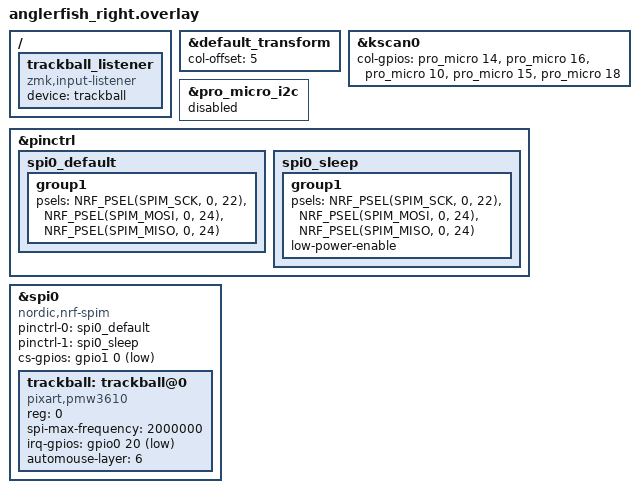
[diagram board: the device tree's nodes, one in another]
#include "anglerfish.dtsi"

&default_transform {
  col-offset = <5>;
};

&kscan0 {
  col-gpios = <&pro_micro 14 GPIO_ACTIVE_HIGH>,
              <&pro_micro 16 GPIO_ACTIVE_HIGH>,
              <&pro_micro 10 GPIO_ACTIVE_HIGH>,
              <&pro_micro 15 GPIO_ACTIVE_HIGH>,
              <&pro_micro 18 GPIO_ACTIVE_HIGH>;
};

&pro_micro_i2c {
    status = "disabled";
};

&pinctrl {
    spi0_default: spi0_default {
        group1 {
            psels = <NRF_PSEL(SPIM_SCK, 0, 22)>,
                <NRF_PSEL(SPIM_MOSI, 0, 24)>,
                <NRF_PSEL(SPIM_MISO, 0, 24)>;
        };
    };

    spi0_sleep: spi0_sleep {
        group1 {
            psels = <NRF_PSEL(SPIM_SCK, 0, 22)>,
                <NRF_PSEL(SPIM_MOSI, 0, 24)>,
                <NRF_PSEL(SPIM_MISO, 0, 24)>;
            low-power-enable;
        };
    };
};

&spi0 {
    status = "okay";
    compatible = "nordic,nrf-spim";
    pinctrl-0 = <&spi0_default>;
    pinctrl-1 = <&spi0_sleep>;
    pinctrl-names = "default", "sleep";
    cs-gpios = <&gpio1 0 GPIO_ACTIVE_LOW>;

    trackball: trackball@0 {
        status = "okay";
        compatible = "pixart,pmw3610";
        reg = <0>;
        spi-max-frequency = <2000000>;
        irq-gpios = <&gpio0 20 (GPIO_ACTIVE_LOW | GPIO_PULL_UP)>;

        /*   optional features   */
        // snipe-layers = <1>;
        // scroll-layers = <2 3>;
        automouse-layer = <6>;
    };
};

/ {
  trackball_listener {
    compatible = "zmk,input-listener";
    device = <&trackball>;
  };
};
